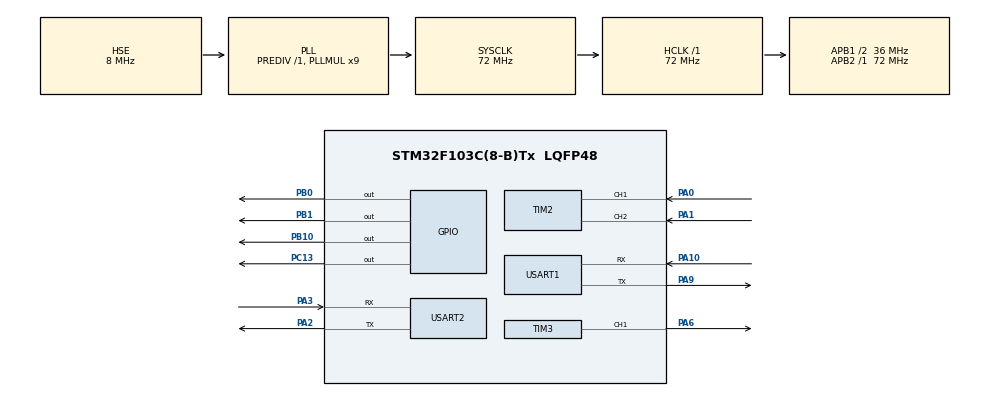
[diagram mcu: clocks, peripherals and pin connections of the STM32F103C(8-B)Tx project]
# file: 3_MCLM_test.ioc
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Dma.Request0=USART1_TX
Dma.Request1=USART2_RX
Dma.Request2=USART2_TX
Dma.USART1_TX.0.Direction=DMA_MEMORY_TO_PERIPH
Dma.USART1_TX.0.Instance=DMA1_Channel4
Dma.USART1_TX.0.MemDataAlignment=DMA_MDATAALIGN_BYTE
Dma.USART1_TX.0.MemInc=DMA_MINC_ENABLE
Dma.USART1_TX.0.Mode=DMA_NORMAL
Dma.USART1_TX.0.PeriphDataAlignment=DMA_PDATAALIGN_BYTE
Dma.USART1_TX.0.PeriphInc=DMA_PINC_DISABLE
Dma.USART1_TX.0.Priority=DMA_PRIORITY_MEDIUM
Dma.USART2_RX.1.Direction=DMA_PERIPH_TO_MEMORY
Dma.USART2_RX.1.Instance=DMA1_Channel6
Dma.USART2_RX.1.MemDataAlignment=DMA_MDATAALIGN_BYTE
Dma.USART2_RX.1.MemInc=DMA_MINC_ENABLE
Dma.USART2_RX.1.Mode=DMA_NORMAL
Dma.USART2_RX.1.PeriphDataAlignment=DMA_PDATAALIGN_BYTE
Dma.USART2_RX.1.PeriphInc=DMA_PINC_DISABLE
Dma.USART2_RX.1.Priority=DMA_PRIORITY_HIGH
Dma.USART2_TX.2.Direction=DMA_MEMORY_TO_PERIPH
Dma.USART2_TX.2.Instance=DMA1_Channel7
Dma.USART2_TX.2.MemDataAlignment=DMA_MDATAALIGN_BYTE
Dma.USART2_TX.2.MemInc=DMA_MINC_ENABLE
Dma.USART2_TX.2.Mode=DMA_NORMAL
Dma.USART2_TX.2.PeriphDataAlignment=DMA_PDATAALIGN_BYTE
Dma.USART2_TX.2.PeriphInc=DMA_PINC_DISABLE
Dma.USART2_TX.2.Priority=DMA_PRIORITY_HIGH
FREERTOS.Queues01=CommandQueue,32,uint64_t,0,Dynamic,NULL,NULL
FREERTOS.Tasks01=MotorControl_Ta,24,192,Start_MotorControl,Default,NULL,Static,MotorControl_TBuffer,MotorControl_TControlBlock;Encoder_Ta,8,128,Start_Encoder,Default,NULL,Static,Encoder_TaskBuffer,Encoder_TaskControlBlock;Logger_Ta,8,384,Start_Logger,Default,NULL,Static,Logger_TaBuffer,Logger_TaControlBlock;Command_Ta,8,128,Start_Command,Default,NULL,Static,Command_TaBuffer,Command_TaControlBlock;Heartbeat_Ta,8,128,Start_Heartbeat,Default,NULL,Static,Heartbeat_TaBuffer,Heartbeat_TaControlBlock
Mcu.Family=STM32F1
Mcu.Name=STM32F103C(8-B)Tx
Mcu.Package=LQFP48
NVIC.DMA1_Channel4_IRQn=true\:5\:0\:false\:false\:true\:true\:false\:true\:true
NVIC.DMA1_Channel6_IRQn=true\:5\:0\:false\:false\:true\:true\:false\:true\:true
NVIC.DMA1_Channel7_IRQn=true\:5\:0\:false\:false\:true\:true\:false\:true\:true
NVIC.PriorityGroup=NVIC_PRIORITYGROUP_4
NVIC.TIM4_IRQn=true\:15\:0\:false\:false\:true\:false\:false\:true\:true
NVIC.TimeBase=TIM4_IRQn
NVIC.TimeBaseIP=TIM4
NVIC.USART1_IRQn=true\:5\:0\:false\:false\:true\:true\:false\:true\:true
NVIC.USART2_IRQn=true\:5\:0\:false\:false\:true\:true\:false\:true\:true
PA0-WKUP.Signal=S_TIM2_CH1_ETR
PA1.Signal=S_TIM2_CH2
PA10.Mode=Asynchronous
PA10.Signal=USART1_RX
PA13.Mode=Serial_Wire
PA13.Signal=SYS_JTMS-SWDIO
PA14.Mode=Serial_Wire
PA14.Signal=SYS_JTCK-SWCLK
PA2.Mode=Asynchronous
PA2.Signal=USART2_TX
PA3.Mode=Asynchronous
PA3.Signal=USART2_RX
PA6.Signal=S_TIM3_CH1
PA9.Mode=Asynchronous
PA9.Signal=USART1_TX
PB0.PinState=GPIO_PIN_SET
PB0.Signal=GPIO_Output
PB1.PinState=GPIO_PIN_SET
PB1.Signal=GPIO_Output
PB10.PinState=GPIO_PIN_SET
PB10.Signal=GPIO_Output
PC13-TAMPER-RTC.PinState=GPIO_PIN_SET
PC13-TAMPER-RTC.Signal=GPIO_Output
PD0-OSC_IN.Mode=HSE-External-Oscillator
PD0-OSC_IN.Signal=RCC_OSC_IN
PD1-OSC_OUT.Mode=HSE-External-Oscillator
PD1-OSC_OUT.Signal=RCC_OSC_OUT
ProjectManager.HeapSize=0x200
ProjectManager.StackSize=0x400
ProjectManager.TargetToolchain=MDK-ARM V5.32
RCC.AHBFreq_Value=72000000
RCC.APB1CLKDivider=RCC_HCLK_DIV2
RCC.APB1Freq_Value=36000000
RCC.APB1TimFreq_Value=72000000
RCC.APB2Freq_Value=72000000
RCC.APB2TimFreq_Value=72000000
RCC.EnbaleCSS=true
RCC.HCLKFreq_Value=72000000
RCC.PLLMUL=RCC_PLL_MUL9
RCC.PLLSourceVirtual=RCC_PLLSOURCE_HSE
RCC.SYSCLKFreq_VALUE=72000000
RCC.SYSCLKSource=RCC_SYSCLKSOURCE_PLLCLK
RCC.USBFreq_Value=72000000
SH.S_TIM2_CH1_ETR.0=TIM2_CH1,Encoder_Interface
SH.S_TIM2_CH2.0=TIM2_CH2,Encoder_Interface
SH.S_TIM3_CH1.0=TIM3_CH1,PWM Generation1 CH1
TIM2.EncoderMode=TIM_ENCODERMODE_TI12
TIM2.IC1Filter=7
TIM2.IC2Filter=7
TIM3.Channel-PWM\ Generation1\ CH1=TIM_CHANNEL_1
TIM3.Period=50-1
TIM3.Prescaler=72-1
USART1.VirtualMode=VM_ASYNC
USART2.VirtualMode=VM_ASYNC
VP_FREERTOS_VS_CMSIS_V2.Mode=CMSIS_V2
VP_SYS_VS_tim4.Mode=TIM4
board=custom

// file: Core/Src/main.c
/* USER CODE BEGIN Header */
/**
  ******************************************************************************
  * @file           : main.c
  * @brief          : Main program body
  ******************************************************************************
  * @attention
  *
  * Copyright (c) 2025 STMicroelectronics.
  * All rights reserved.
  *
  * This software is licensed under terms that can be found in the LICENSE file
  * in the root directory of this software component.
  * If no LICENSE file comes with this software, it is provided AS-IS.
  *
  ******************************************************************************
  */
/* USER CODE END Header */
#include "main.h"
#include "cmsis_os.h"
#include "dma.h"
#include "tim.h"
#include "usart.h"
#include "gpio.h"

/* USER CODE BEGIN Includes */

#include "app_includes.h"    // 统一应用层头文件

// "app_task.h"已经包含在"app_includes.h"
// #include "app_task.h"

// #include "string.h"   // 引入字符串处理库
// #include "tb6612_DC.h"    // 引入电机控制模块
// #include "command.h"  // 引入命令解析模块
// #include "logger.h" // 引入 UART 应用层模块

/* USER CODE END Includes */

/* USER CODE BEGIN PV */

// Motor_t motor1; // 声明全局电机实例

/* USER CODE END PV */

void SystemClock_Config(void);
void MX_FREERTOS_Init(void);

int main(void)
{

  /* MCU Configuration--------------------------------------------------------*/

  /* Reset of all peripherals, Initializes the Flash interface and the Systick. */
  HAL_Init();

  /* Configure the system clock */
  SystemClock_Config();

  /* Initialize all configured peripherals */
  MX_GPIO_Init();
  MX_DMA_Init();
  MX_TIM2_Init();
  MX_TIM3_Init();
  MX_USART1_UART_Init();
  MX_USART2_UART_Init();
  /* USER CODE BEGIN 2 */

  // 已经完成迁移20251212

  // UART_App_Init();

  // // 启动编码器计数
  // HAL_TIM_Encoder_Start(&htim2, TIM_CHANNEL_ALL);

  // Motor_Init(&motor1, &htim3, TIM_CHANNEL_1,
  //             GPIOB, GPIO_PIN_0,
  //             GPIOB, GPIO_PIN_1,
  //             GPIOB, GPIO_PIN_10,              // EN (如果没有独立的使能引脚，则为 NULL, 0)
  //             1000, 1000, 5,
  //             0, MOTOR_STOP_BRAKE);

  /* USER CODE END 2 */

  /* Init scheduler */
  osKernelInitialize();  /* Call init function for freertos objects (in cmsis_os2.c) */
  MX_FREERTOS_Init();

  /* Start scheduler */
  osKernelStart();

  /* We should never get here as control is now taken by the scheduler */

  /* Infinite loop */
  while (1)
  {

  }
}

void SystemClock_Config(void)
{
  RCC_OscInitTypeDef RCC_OscInitStruct = {0};
  RCC_ClkInitTypeDef RCC_ClkInitStruct = {0};

  /** Initializes the RCC Oscillators according to the specified parameters
  * in the RCC_OscInitTypeDef structure.
  */
  RCC_OscInitStruct.OscillatorType = RCC_OSCILLATORTYPE_HSE;
  RCC_OscInitStruct.HSEState = RCC_HSE_ON;
  RCC_OscInitStruct.HSEPredivValue = RCC_HSE_PREDIV_DIV1;
  RCC_OscInitStruct.HSIState = RCC_HSI_ON;
  RCC_OscInitStruct.PLL.PLLState = RCC_PLL_ON;
  RCC_OscInitStruct.PLL.PLLSource = RCC_PLLSOURCE_HSE;
  RCC_OscInitStruct.PLL.PLLMUL = RCC_PLL_MUL9;
  if (HAL_RCC_OscConfig(&RCC_OscInitStruct) != HAL_OK)
  {
    Error_Handler();
  }

  /** Initializes the CPU, AHB and APB buses clocks
  */
  RCC_ClkInitStruct.ClockType = RCC_CLOCKTYPE_HCLK|RCC_CLOCKTYPE_SYSCLK
                              |RCC_CLOCKTYPE_PCLK1|RCC_CLOCKTYPE_PCLK2;
  RCC_ClkInitStruct.SYSCLKSource = RCC_SYSCLKSOURCE_PLLCLK;
  RCC_ClkInitStruct.AHBCLKDivider = RCC_SYSCLK_DIV1;
  RCC_ClkInitStruct.APB1CLKDivider = RCC_HCLK_DIV2;
  RCC_ClkInitStruct.APB2CLKDivider = RCC_HCLK_DIV1;

  if (HAL_RCC_ClockConfig(&RCC_ClkInitStruct, FLASH_LATENCY_2) != HAL_OK)
  {
    Error_Handler();
  }

  /** Enables the Clock Security System
  */
  HAL_RCC_EnableCSS();
}

void HAL_TIM_PeriodElapsedCallback(TIM_HandleTypeDef *htim)
{
  if (htim->Instance == TIM4)
  {
    HAL_IncTick();
  }
}

void Error_Handler(void)
{
  __disable_irq();
  while (1)
  {
  }
}

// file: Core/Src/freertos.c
/* USER CODE BEGIN Header */
/**
  ******************************************************************************
  * File Name          : freertos.c
  * Description        : Code for freertos applications
  ******************************************************************************
  * @attention
  *
  * Copyright (c) 2025 STMicroelectronics.
  * All rights reserved.
  *
  * This software is licensed under terms that can be found in the LICENSE file
  * in the root directory of this software component.
  * If no LICENSE file comes with this software, it is provided AS-IS.
  *
  ******************************************************************************
  */
/* USER CODE END Header */

#include "FreeRTOS.h"
#include "task.h"
#include "main.h"
#include "cmsis_os.h"

/* USER CODE BEGIN Includes */

#include "app_task.h"

/* USER CODE END Includes */

typedef StaticTask_t osStaticThreadDef_t;

/* Definitions for MotorControl_Ta */
osThreadId_t MotorControl_TaHandle;
uint32_t MotorControl_TBuffer[ 192 ];
osStaticThreadDef_t MotorControl_TControlBlock;
const osThreadAttr_t MotorControl_Ta_attributes = {
  .name = "MotorControl_Ta",
  .cb_mem = &MotorControl_TControlBlock,
  .cb_size = sizeof(MotorControl_TControlBlock),
  .stack_mem = &MotorControl_TBuffer[0],
  .stack_size = sizeof(MotorControl_TBuffer),
  .priority = (osPriority_t) osPriorityNormal,
};
/* Definitions for Encoder_Ta */
osThreadId_t Encoder_TaHandle;
uint32_t Encoder_TaskBuffer[ 128 ];
osStaticThreadDef_t Encoder_TaskControlBlock;
const osThreadAttr_t Encoder_Ta_attributes = {
  .name = "Encoder_Ta",
  .cb_mem = &Encoder_TaskControlBlock,
  .cb_size = sizeof(Encoder_TaskControlBlock),
  .stack_mem = &Encoder_TaskBuffer[0],
  .stack_size = sizeof(Encoder_TaskBuffer),
  .priority = (osPriority_t) osPriorityLow,
};
/* Definitions for Logger_Ta */
osThreadId_t Logger_TaHandle;
uint32_t Logger_TaBuffer[ 384 ];
osStaticThreadDef_t Logger_TaControlBlock;
const osThreadAttr_t Logger_Ta_attributes = {
  .name = "Logger_Ta",
  .cb_mem = &Logger_TaControlBlock,
  .cb_size = sizeof(Logger_TaControlBlock),
  .stack_mem = &Logger_TaBuffer[0],
  .stack_size = sizeof(Logger_TaBuffer),
  .priority = (osPriority_t) osPriorityLow,
};
/* Definitions for Command_Ta */
osThreadId_t Command_TaHandle;
uint32_t Command_TaBuffer[ 128 ];
osStaticThreadDef_t Command_TaControlBlock;
const osThreadAttr_t Command_Ta_attributes = {
  .name = "Command_Ta",
  .cb_mem = &Command_TaControlBlock,
  .cb_size = sizeof(Command_TaControlBlock),
  .stack_mem = &Command_TaBuffer[0],
  .stack_size = sizeof(Command_TaBuffer),
  .priority = (osPriority_t) osPriorityLow,
};
/* Definitions for Heartbeat_Ta */
osThreadId_t Heartbeat_TaHandle;
uint32_t Heartbeat_TaBuffer[ 128 ];
osStaticThreadDef_t Heartbeat_TaControlBlock;
const osThreadAttr_t Heartbeat_Ta_attributes = {
  .name = "Heartbeat_Ta",
  .cb_mem = &Heartbeat_TaControlBlock,
  .cb_size = sizeof(Heartbeat_TaControlBlock),
  .stack_mem = &Heartbeat_TaBuffer[0],
  .stack_size = sizeof(Heartbeat_TaBuffer),
  .priority = (osPriority_t) osPriorityLow,
};
/* Definitions for CommandQueue */
osMessageQueueId_t CommandQueueHandle;
const osMessageQueueAttr_t CommandQueue_attributes = {
  .name = "CommandQueue"
};

void Start_MotorControl(void *argument);
void Start_Encoder(void *argument);
void Start_Logger(void *argument);
void Start_Command(void *argument);
void Start_Heartbeat(void *argument);

void MX_FREERTOS_Init(void); /* (MISRA C 2004 rule 8.1) */

void MX_FREERTOS_Init(void) {

  /* Create the queue(s) */
  /* creation of CommandQueue */
  CommandQueueHandle = osMessageQueueNew (32, sizeof(uint64_t), &CommandQueue_attributes);

  /* Create the thread(s) */
  /* creation of MotorControl_Ta */
  MotorControl_TaHandle = osThreadNew(Start_MotorControl, NULL, &MotorControl_Ta_attributes);

  /* creation of Encoder_Ta */
  Encoder_TaHandle = osThreadNew(Start_Encoder, NULL, &Encoder_Ta_attributes);

  /* creation of Logger_Ta */
  Logger_TaHandle = osThreadNew(Start_Logger, NULL, &Logger_Ta_attributes);

  /* creation of Command_Ta */
  Command_TaHandle = osThreadNew(Start_Command, NULL, &Command_Ta_attributes);

  /* creation of Heartbeat_Ta */
  Heartbeat_TaHandle = osThreadNew(Start_Heartbeat, NULL, &Heartbeat_Ta_attributes);

}

void Start_MotorControl(void *argument)
{
  /* USER CODE BEGIN Start_MotorControl */
  /* Infinite loop */
  MotorControl_Task(argument);
  // for(;;)
  // {
  //   // MotorControl_Task();  // 从原来300行变成1行
  //   osDelay(10);
  // }
  /* USER CODE END Start_MotorControl */
}

void Start_Encoder(void *argument)
{
  /* USER CODE BEGIN Start_Encoder */
  /* Infinite loop */
  Encoder_Task(argument);
  // for(;;)
  // {
  //   // Encoder_Task();       // 专门速度更新和标志位设置
  //   osDelay(10);
  // }
  /* USER CODE END Start_Encoder */
}

void Start_Logger(void *argument)
{
  /* USER CODE BEGIN Start_Logger */
  /* Infinite loop */
  Logger_Task(argument);
  // for(;;)
  // {
  //   // Logger_Task();        // 串口发送和格式化
  //   osDelay(1);
  // }
  /* USER CODE END Start_Logger */
}

void Start_Command(void *argument)
{
  /* USER CODE BEGIN Start_Command */
  /* Infinite loop */
  // Command_Task(argument);
  for(;;)
  {
    osDelay(1);
  }
  /* USER CODE END Start_Command */
}

void Start_Heartbeat(void *argument)
{
  /* USER CODE BEGIN Start_Heartbeat */
  /* Infinite loop */
  // (void)argument; // 明确忽略
  // Heartbeat_Task();   // 不再传 argument

  Heartbeat_Task(argument);

  /* USER CODE END Start_Heartbeat */
}
